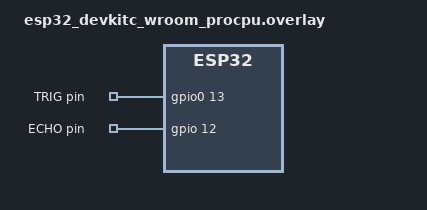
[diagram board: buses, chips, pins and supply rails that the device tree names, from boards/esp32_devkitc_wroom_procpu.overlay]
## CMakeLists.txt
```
cmake_minimum_required(VERSION 3.20.0)

set(BOARD esp32_devkitc_wroom)
find_package(Zephyr REQUIRED HINTS $ENV{ZEPHYR_BASE})
project(level-meter)
file(GLOB SOURCES src/**/*.c src/*.c)
#zephyr_include_directories(tests)
target_sources(app PRIVATE ${SOURCES})
#target_sources(app PRIVATE tests/src/test_main.c)
#target_sources(app PRIVATE tests/src/modules/test_hcsr04.c)
```

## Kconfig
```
menu "Water-meter Configuration"
    config POLLING_DELAY_MS
        int "Polling delay in ms"
        default 4000
endmenu

source "Kconfig.zephyr"
```

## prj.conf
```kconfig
CONFIG_LOG_MODE_IMMEDIATE=y
CONFIG_HEAP_MEM_POOL_SIZE=1024 
CONFIG_BT=y
CONFIG_LOG=y
CONFIG_BT_SMP=y
CONFIG_BT_PERIPHERAL=y
CONFIG_SETTINGS_RUNTIME=y
CONFIG_BT_DIS=y
CONFIG_BT_DIS_PNP=n
CONFIG_BT_DIS_SETTINGS=y
CONFIG_BT_DIS_MODEL="Water-meter"
CONFIG_BT_DIS_SERIAL_NUMBER=y
CONFIG_BT_DIS_SERIAL_NUMBER_STR="0001"

CONFIG_BT_MAX_CONN=1
CONFIG_BT_ATT_PREPARE_COUNT=5
CONFIG_BT_BAS=y
CONFIG_BT_PRIVACY=y
CONFIG_BT_DEVICE_NAME="Water-meter"
CONFIG_BT_DEVICE_APPEARANCE=1362
CONFIG_BT_DEVICE_NAME_DYNAMIC=y
CONFIG_BT_DEVICE_NAME_MAX=65
CONFIG_BT_FIXED_PASSKEY=y
CONFIG_BT_LOG_LEVEL_OFF=y
CONFIG_BT_BAS_LOG_LEVEL_OFF=y
CONFIG_BT_HRS_LOG_LEVEL_OFF=y
CONFIG_BT_TPS_LOG_LEVEL_OFF=y
CONFIG_BT_IAS_LOG_LEVEL_OFF=y
CONFIG_BT_OTS_LOG_LEVEL_OFF=y
CONFIG_GPIO=y
CONFIG_RING_BUFFER=y
CONFIG_SHELL=y
CONFIG_ZTEST=y
CONFIG_TEST=y
CONFIG_TEST_RANDOM_GENERATOR=y
```

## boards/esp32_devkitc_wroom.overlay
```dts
/ {
    hcsr04 {
        compatible = "gpio-keys";
        trig: trig {
            gpios = <&gpio0 13 GPIO_ACTIVE_HIGH>;
            label = "TRIG pin";
        };
        echo: echo {
            gpios = <&gpio0 12 GPIO_ACTIVE_HIGH>;
            label = "ECHO pin";
        };
    };
};
```

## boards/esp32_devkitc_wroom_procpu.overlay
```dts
/ {
	aliases {
		trigger = &trig;
		echo = &echo;
	};

	hcsr04 {
		compatible = "gpio-keys";

		trig: trig {
			gpios = <&gpio0 13 GPIO_ACTIVE_HIGH>;
			label = "TRIG pin";
		};

		echo: echo {
			gpios = <&gpio 12 GPIO_ACTIVE_HIGH>;
			label = "ECHO pin";
		};
	};
};
```

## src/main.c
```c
#include "modules/ble_lm.h"
#include "modules/hcsr04.h"
#include "modules/data_manager.h"
#include "modules/guards.h"

#include <stdio.h>
#include <stdlib.h>
#include <zephyr/shell/shell.h>

static void send_alarm(const struct shell *shell, size_t argc, char **argv);
static void send_critical_alarm(const struct shell *shell, size_t argc, char **argv);
static void get_man_data(const struct shell *shell, size_t argc, char **argv);
static void get_man_data_bulk(const struct shell *shell, size_t argc, char **argv);

SHELL_CMD_REGISTER(alarm, NULL, "Sends an alarm through BLE", send_alarm);
SHELL_CMD_REGISTER(critical_alarm, NULL, "Sends an critical alarm through BLE",
		   send_critical_alarm);
SHELL_CMD_REGISTER(man_get, NULL, "Gets last data polled by the manager", get_man_data);
SHELL_CMD_REGISTER(man_get_bulk, NULL, "Gets last n data polled by the manager", get_man_data_bulk);

int main(void)
{
	struct data_man_conf conf = {
		.poll_interval = K_MSEC(CONFIG_POLLING_DELAY_MS),
		.alarm_threshold = 10,
		.critical_alarm_threshold = 5,
	};
	LM_CHECK_ERROR(ble_init());
	LM_CHECK_ERROR(data_man_init(10, &conf));
	LM_CHECK_ERROR(hcsr04_init());

	return 0;
}

static void handle_alarm(size_t argc, char **argv, int (*send)(struct hcsr04_data *))
{
	if (argc != 2) {
		printf("Usage: %s <distance>\n", argv[0]);
		return;
	}

	uint32_t distance = atoi(argv[1]);
	if (distance <= 0) {
		printf("The distance must be positive!\n");
		return;
	}

	k_timepoint_t timepoint;
	timepoint.tick = k_uptime_ticks();

	struct hcsr04_data data;
	data.distance = distance;
	data.timestamp = timepoint;

	int ret = send(&data);
	if (ret == 0) {
		printf("Alarm was sent\n");
	} else {
		printf("An error ocurred: %d\n", ret);
	}
}

static void send_alarm(const struct shell *shell, size_t argc, char **argv)
{
	handle_alarm(argc, argv, ble_send_alarm);
}

static void send_critical_alarm(const struct shell *shell, size_t argc, char **argv)
{
	handle_alarm(argc, argv, ble_send_critical_alarm);
}

static void get_man_data(const struct shell *shell, size_t argc, char **argv)
{
	struct hcsr04_data data;
	data_man_get(&data);
	printf("Distance: %d\nTimestamp: %lld\n", data.distance, data.timestamp.tick);
}

static void get_man_data_bulk(const struct shell *shell, size_t argc, char **argv)
{
	if (argc != 2) {
		printf("Usage: %s <n>\n", argv[0]);
		return;
	}

	int n = atoi(argv[1]);
	if (n <= 0) {
		printf("n must be positive!\n");
		return;
	}

	struct hcsr04_data *data = (struct hcsr04_data *)k_malloc(sizeof(struct hcsr04_data) * n);

	int ret = data_man_get_bulk(&data, n);
	if (ret != 0) {
		printf("An error ocurred: %d\n", ret);
		return;
	}

	for (int i = 0; i < n; i++) {
		printf("[%d]\nDistance: %d\nTimestamp: %lld\n", i, data[i].distance,
		       data[i].timestamp.tick);
	}
	k_free(data);
}
```
